# GD32H71x_72x register map
File version: 1.0
CPU: CM7 r1p2, little endian, MPU, FPU, 4 interrupt priority bits
Registers are 32-bit, read-write, reset 0x0 unless marked. A register's access mark holds for its fields unless they carry their own. Offsets are from the block's base; [hi:lo] are bit positions.

## MDIO — Management data input / output
Base 0x40009400
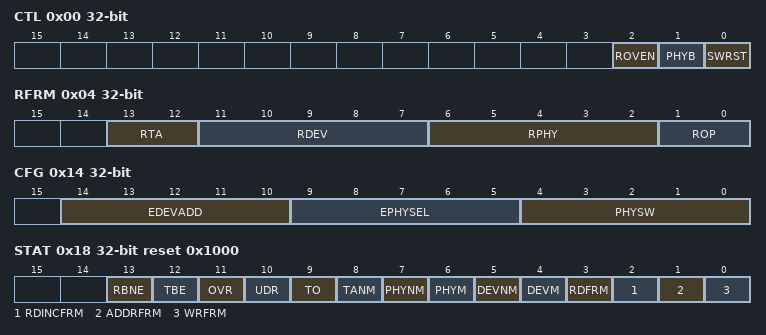
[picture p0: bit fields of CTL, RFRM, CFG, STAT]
0x00 CTL access per field — Control register
  [2] ROVEN rw — Receive overrun enable
  [1] PHYB rw — MDIO PHY bit length
  [0] SWRST wo — Write 1 to reset MDIO block. Registers will not be reset. Hardware immediately clears this bit.
0x04 RFRM ro — Received frame information register
  [13:12] RTA — Received frame field TA (only accept TA bits of a write data frame or a write address frame)
  [11:7] RDEV — Received frame field DEVADD
  [6:2] RPHY — Received frame field PHYADR
  [1:0] ROP — Received frame field OP
0x08 RDATA ro — Received data register
  [15:0] RDATA — Received frame field DATA
0x0C RADDR ro — Received address register
  [15:0] RADDR — Received frame field ADDRESS
0x10 TDATA — Transfer data register
  [15:0] TDATA — Data that is transmitted by the next read or post read increment address frame. Before a read data frame, the master sends a write address frame to specify which data is to be read. After this write address frame, the user software must place this requested data into MDIO_TDATA before it is required by the read frame. The time available is at latest 3 MDIO clock cycles before TA.
0x14 CFG — Configuration register
  [14:10] EDEVADD — Expected DEVADD. Normally 01.
  [9:5] EPHYSEL — Selects expected PHYADR. For each bit x in the 5-bit EPHYSEL:
  [4:0] PHYSW — Software provided PHYADR. Chosen according to corresponding EPHYSEL[4:0] bits.
0x18 STAT ro reset 0x1000 — Status register
  [13] RBNE — Read data buffer not empty flag. Data is received and ready to be read. Cleared by reading the MDIO_RDATA register.
  [12] TBE — Transfer data buffer empty flag. The bit is reset by writing the MDIO_TDATA register.
  [11] OVR — Receive overrun flag. Set by hardware when the data in the receive shift register is ready to be transferred into the MDIO_RDATA register while the RBNE bit is set. Cleared by reading the MDIO_STAT register.
  [10] UDR — Transmit underrun flag
  [9] TO — Timeout flag
  [8] TANM — Set at end bit of TA of a write data frame or a write address frame if the received TA no matches expected 10. Cleared by reading the MDIO_STAT register.
  [7] PHYNM — Set at end bit of PHYADR if PHYADR nonmatches. Cleared by reading the MDIO_STAT register.
  [6] PHYM — Set at end bit of PHYADR if PHYADR matches. Cleared by reading the MDIO_STAT register.
  [5] DEVNM — Set at end bit of DEVADD if DEVADD nonmatches. Cleared by reading the MDIO_STAT register.
  [4] DEVM — Set at end bit of DEVADD if DEVADD matches. Cleared by reading the MDIO_STAT register.
  [3] RDFRM — Set at end bit (after frame field DATA transmission) of a read data frame if DEVADD and PHYADR both match. Cleared by reading the MDIO_STAT register.
  [2] RDINCFRM — Set at end bit (after frame field DATA transmission) of a post read increment address frame if DEVADD and PHYADR both match. Cleared by reading MDIO_STAT register.
  [1] ADDRFRM — Set at end bit of a write address frame if DEVADD and PHYADR both match. Cleared by reading the MDIO_STAT register.
  [0] WRFRM — Set at end bit of a write data frame if DEVADD and PHYADR both match. Cleared by reading the MDIO_STAT register.
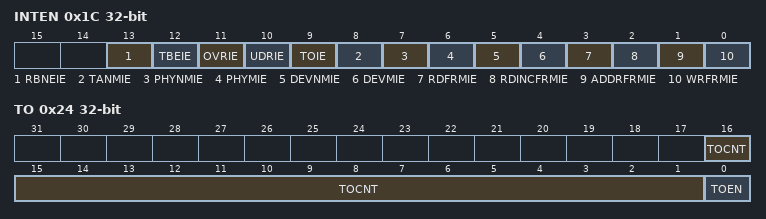
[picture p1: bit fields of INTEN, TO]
0x1C INTEN — Interrupt enable register
  [13] RBNEIE — If set, interrupt is requested when RBNE bit in MDIO_STAT register becomes active.
  [12] TBEIE — If set, interrupt is requested when TBEE bit in MDIO_STAT register becomes active.
  [11] OVRIE — If set, interrupt is requested when OVR bit in MDIO_STAT register becomes active.
  [10] UDRIE — If set, interrupt is requested when UDR bit in MDIO_STAT register becomes active.
  [9] TOIE — If set, interrupt is requested when TO bit in MDIO_STAT register becomes active.
  [8] TANMIE — If set, interrupt is requested when TANM bit in MDIO_STAT register becomes active.
  [7] PHYNMIE — If set, interrupt is requested when PHYNM bit in MDIO_STAT register becomes active.
  [6] PHYMIE — If set, interrupt is requested when PHYM bit in MDIO_STAT register becomes active.
  [5] DEVNMIE — If set, interrupt is requested when DEVNM bit in MDIO_STAT register becomes active.
  [4] DEVMIE — If set, interrupt is requested when DEVM bit in MDIO_STAT register becomes active.
  [3] RDFRMIE — If set, interrupt is requested when RDFRM bit in MDIO_STAT register becomes active.
  [2] RDINCFRMIE — If set, interrupt is requested when RDINCFRM bit in MDIO_STAT register becomes active.
  [1] ADDRFRMIE — If set, interrupt is requested when ADDRFRM bit in MDIO_STAT register becomes active.
  [0] WRFRMIE — If set, interrupt is requested when WRFRM bit in MDIO_STAT register becomes active.
0x20 PIN ro — Pin value register
  [4:0] PHYPIN — Pin value read from hardware MDIO_Ax pins
0x24 TO — Timeout register
  [16:1] TOCNT — MDIO time out = TOCNT[15:0] * PCLK1
  [0] TOEN — Timeout enable
